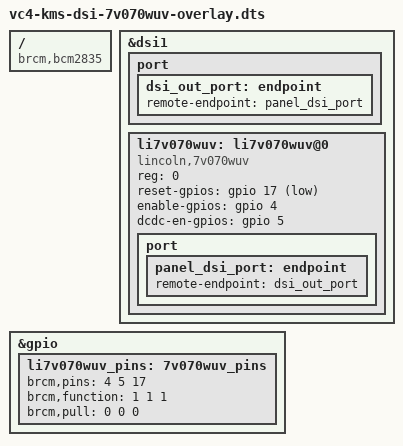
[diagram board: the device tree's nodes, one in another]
/*
 * Device Tree overlay to connect a lincoln 7v070wuv DSI panel to DSI1.
 * This uses 4 DSI data lanes, so can only be used with a Compute Module.
 *
 * Credit to forum user gizmomouse on
 * https://www.raspberrypi.org/forums/viewtopic.php?f=98&t=253912 and
 * Andrey Vostrukhin of Harlab for the overlay.
 *
 * Refer to https://github.com/harlab/CM4_LCD_7v070wuv for schematics and
 * other documentation.
 */

/dts-v1/;
/plugin/;

/ {
	compatible = "brcm,bcm2835";

	fragment@0 {
		target = <&dsi1>;
		__overlay__{
			status = "okay";
			#address-cells = <1>;
			#size-cells = <0>;
			port {
				dsi_out_port:endpoint {
					remote-endpoint = <&panel_dsi_port>;
				};
			};

			li7v070wuv:li7v070wuv@0 {
				compatible    = "lincoln,7v070wuv";
				status        = "okay";
				reg           = <0>;
				reset-gpios   = <&gpio 17 1>;   // LCD RST
				enable-gpios  = <&gpio 4 0>;    // LCD Enable
				dcdc-en-gpios = <&gpio 5 0>;    // LCD DC-DC Enable
				port {
					panel_dsi_port: endpoint {
						remote-endpoint = <&dsi_out_port>;
					};
				};
			};
		};
	};

	fragment@1 {
		target = <&gpio>;
		__overlay__ {
			li7v070wuv_pins: 7v070wuv_pins {
				brcm,pins = <4 5 17>;
				brcm,function = <1 1 1>; // out
				brcm,pull = <0 0 0>; // off
			};
		};

	};

	__overrides__ {
		reset = <&li7v070wuv_pins>,"brcm,pins:8",
			<&li7v070wuv>,"reset-gpios:4";

		enable = <&li7v070wuv_pins>,"brcm,pins:0",
			<&li7v070wuv>,"enable-gpios:4";

		dcdc-en = <&li7v070wuv_pins>,"brcm,pins:4",
			<&li7v070wuv>,"dcdc-en-gpios:4";
	};
};
